AUTOSAR XML (schema 00044)
package /ComponentTypes
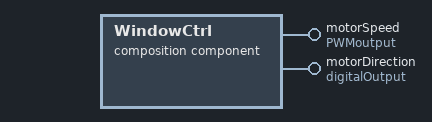
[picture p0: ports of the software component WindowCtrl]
  composition sw component type WindowCtrl
    provide port motorSpeed: nonqueued-sender-com-spec=dutyCycle, provided-interface=PWMoutput
    provide port motorDirection: nonqueued-sender-com-spec=outputStatus, provided-interface=digitalOutput
    6 x component:
      switchDetector: type=switchDetector
      motorControl: type=motorControl
      pinchDetector: type=pinchDetector
      UPswitch: type=doorSwitch
      DOWNswitch: type=doorSwitch
      pinchSwitch: type=pinchSwitch
    delegate motorControl.motorPWM <-> outer port motorSpeed
    delegate switchDetector.motorDir <-> outer port motorDirection
    connect pinchDetector.motorStop -> motorControl.EStop
    connect switchDetector.motorStatus -> motorControl.motorOnOff
    connect UPswitch.switchState -> switchDetector.UpSwitchInput
    connect DOWNswitch.switchState -> switchDetector.DownSwitchInput
    connect pinchSwitch.pinchDetected -> pinchDetector.pinchDetect
